VERSION "HIPBNYYYYYYYYYYYYYYYYYYYYYYYYYYYYYYYYYYYYY/4/%%%/4/'%**4YYY///"

NS_ :

BS_:

BU_:

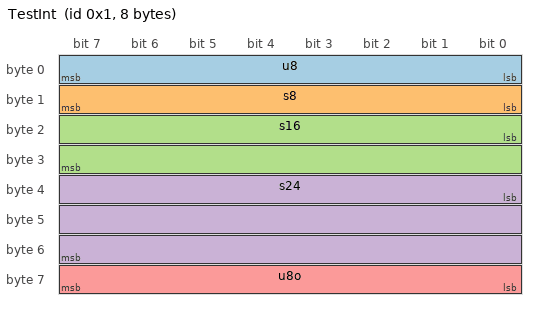
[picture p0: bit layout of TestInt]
BO_ 1 TestInt: 8 Vector__XXX
 SG_ u8 : 0|8@1+ (1,0) [0|0] "" Vector__XXX
 SG_ s8 : 8|8@1- (1,0) [0|0] "" Vector__XXX
 SG_ s16 : 16|16@1- (1,0) [0|0] "" Vector__XXX
 SG_ s24 : 32|24@1- (1,0) [0|0] "" Vector__XXX
 SG_ u8o : 56|8@1+ (1,0) [0|0] "" Vector__XXX

BO_ 2 test64bit: 8 Vector__XXX
 SG_ signed64 : 0|64@1- (1,0) [0|0] "" Vector__XXX

BO_ 3 NewMessage_3: 8 Vector__XXX
 SG_ Afloat : 0|32@1- (1,0) [0|0] "" Vector__XXX
 SG_ Bfloat : 32|32@1- (1,0) [0|0] "" Vector__XXX

BO_ 4 Double: 8 Vector__XXX
 SG_ Adouble : 0|64@1- (1,0) [0|0] "" Vector__XXX

BA_DEF_ BO_  "VFrameFormat" ENUM  "StandardCAN","ExtendedCAN","reserved","J1939PG","reserved","reserved","reserved","reserved","reserved","reserved","reserved","reserved","reserved","reserved","StandardCAN_FD","ExtendedCAN_FD";
BA_DEF_ BO_  "CANFD_BRS" ENUM  "0","1";
BA_DEF_DEF_  "VFrameFormat" "StandardCAN";
BA_DEF_DEF_  "CANFD_BRS" "0";
SIG_VALTYPE_ 3 Afloat : 1;
SIG_VALTYPE_ 3 Bfloat : 1;
SIG_VALTYPE_ 4 Adouble : 2;
